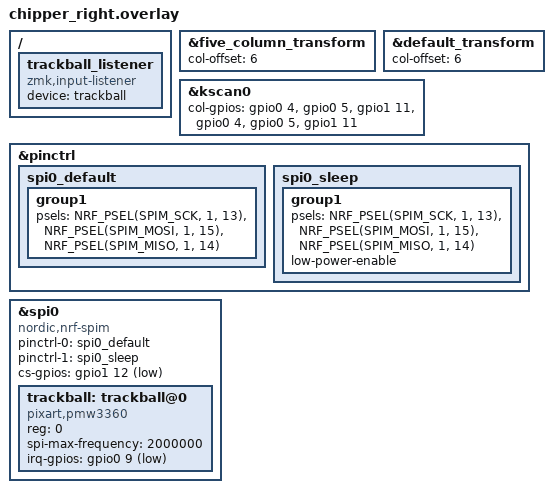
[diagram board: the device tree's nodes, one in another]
/*
 * Copyright (c) 2020 Pete Johanson
 *
 * SPDX-License-Identifier: MIT
 */

#include "chipper.dtsi"

&five_column_transform {
	col-offset = <6>;
};

&default_transform {
	col-offset = <6>;
};


&kscan0 {
	col-gpios
		= <&gpio0 4 GPIO_ACTIVE_HIGH>   //Col0
		, <&gpio0 5 GPIO_ACTIVE_HIGH>   //Col1
		, <&gpio1 11 GPIO_ACTIVE_HIGH>   //Col2
		, <&gpio0 4 GPIO_ACTIVE_HIGH>   //Col1
		, <&gpio0 5 GPIO_ACTIVE_HIGH>   //Col1
		, <&gpio1 11 GPIO_ACTIVE_HIGH>   //Col2
		;
};


&pinctrl {
    spi0_default: spi0_default {
        group1 {
            psels = <NRF_PSEL(SPIM_SCK, 1, 13)>,
                <NRF_PSEL(SPIM_MOSI, 1, 15)>,
                <NRF_PSEL(SPIM_MISO, 1, 14)>;
        };
    };

    spi0_sleep: spi0_sleep {
        group1 {
            psels = <NRF_PSEL(SPIM_SCK, 1, 13)>,
                <NRF_PSEL(SPIM_MOSI, 1, 15)>,
                <NRF_PSEL(SPIM_MISO, 1, 14)>;
            low-power-enable;
        };
    };
};

&spi0 {
    status = "okay";
    compatible = "nordic,nrf-spim";
    pinctrl-0 = <&spi0_default>;
    pinctrl-1 = <&spi0_sleep>;
    pinctrl-names = "default", "sleep";
    cs-gpios = <&gpio1 12 GPIO_ACTIVE_LOW>;

    trackball: trackball@0 {
        status = "okay";
        compatible = "pixart,pmw3360";
        reg = <0>;
        spi-max-frequency = <2000000>;
        irq-gpios = <&gpio0 9 (GPIO_ACTIVE_LOW | GPIO_PULL_UP)>;
    };
};



/ {
  trackball_listener {
    compatible = "zmk,input-listener";
    device = <&trackball>;

  };
};
